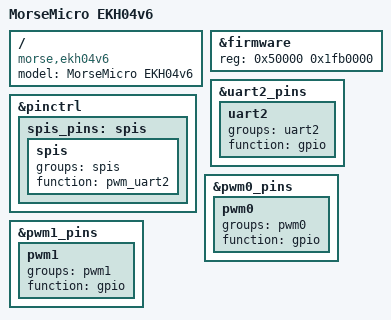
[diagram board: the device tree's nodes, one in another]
#include "mt7628an_morse_ekh03.dtsi"
#include "mt7628an_morse_ekh03_rgbled.dtsi"

/ {
	compatible = "morse,ekh04v6", "mediatek,mt7628an-soc";
	model = "MorseMicro EKH04v6";
};

&firmware {
	reg = <0x50000 0x1fb0000>;
};

&uart2_pins {
	uart2 {
		groups = "uart2";
		function = "gpio";
	};
};

&pinctrl {
	spis_pins: spis{
		spis{
			groups = "spis";
			function = "pwm_uart2";
		};
	};
};

&pwm0_pins {
	pwm0 {
		groups = "pwm0";
		function = "gpio";
	};
};

&pwm1_pins {
	pwm1 {
		groups = "pwm1";
		function = "gpio";
	};
};
